# PIC32MZ2048EFM144 device description
Architecture: MIPS; Family: PIC32MZEF; Series: PIC32MZ
Registers are 32-bit, read-write, no defined reset value unless marked. A register's access mark holds for its fields unless they carry their own. Offsets are from the block's base; [hi:lo] are bit positions; {n}, {i} and the like mark numbered series; 'fields as' and 'values as' point back to an identical list; <NAME> marks a mode.

## ADCHS
Instances: ADCHS 0x1f84b000 in periph_pb3_std
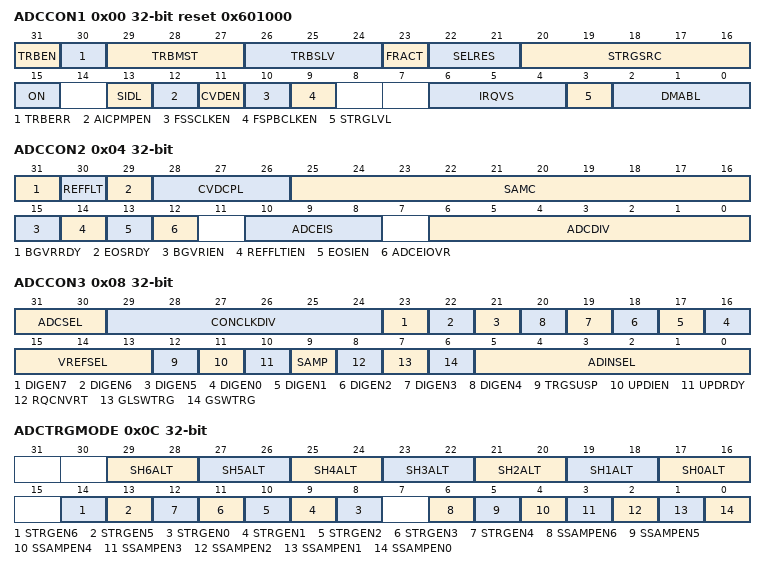
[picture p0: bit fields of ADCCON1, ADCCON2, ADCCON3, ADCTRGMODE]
0x00 ADCCON1 reset 0x601000 — ADC Control Register 1
  [31] TRBEN — Turbo Channel Enable bit
    1=Enable the Turbo channel; 0=Disable the Turbo channel
  [30] TRBERR — Turbo Channel Error Status bit
    1=An error occurred while setting the Turbo channel and Turbo channel function to be disabled regardless of the TRBEN bit being set to 1; 0=Turbo channel error did not occur
  [29:27] TRBMST — Turbo Master ADCx bits
    {v}=ADC{v} is selected as the Turbo Master (v=0..4)
  [26:24] TRBSLV — Turbo Slave ADCx bits
    {v}=ADC{v} is selected as the Turbo Slave (v=0..4)
  [23] FRACT — Fractional Data Output Format bit
    1=Fractional; 0=Integer
  [22:21] SELRES — Shared ADC Resolution bits
    3=12 bits (default); 2=10 bits; 1=8 bits; 0=6 bits
  [20:16] STRGSRC — Scan Trigger Source Select bits
    12=Comparator 2 (COUT); 11=Comparator 1 (COUT); 10=OCMP5; 9=OCMP3; 8=OCMP1; 7=TMR5 match; 6=TMR3 match; 5=TMR1 match; 4=INT0 External interrupt; 2=Global level software trigger (GLSWTRG); 1=Global software edge trigger (GSWTRG); 0=No Trigger
  [15] ON — ADC Module Enable bit
    1=ADC module is enabled; 0=ADC module is disabled
  [13] SIDL — Stop in Idle Mode bit
    1=Discontinue module operation when device enters Idle mode; 0=Continue module operation in Idle mode
  [12] AICPMPEN — Analog Input Charge Pump Enable bit - see datasheet
    1=Analog input charge pump is enabled (default); 0=Analog input charge pump is disabled
  [11] CVDEN — Capacitive Voltage Division Enable bit
    1=CVD operation is enabled; 0=CVD operation is disabled
  [10] FSSCLKEN — Fast Synchronous System Clock to ADC Control Clock bit
    1=Fast synchronous system clock to ADC control clock is enabled; 0=Fast synchronous system clock to ADC control clock is disabled
  [9] FSPBCLKEN — Fast Synchronous Peripheral Clock to ADC Control Clock bit
    1=Fast synchronous peripheral clock to ADC control clock is enabled; 0=Fast synchronous peripheral clock to ADC control clock is disabled
  [6:4] IRQVS — Interrupt Vector Shift bits
    {v}=Shift x left {v} bit position (v=0..7)
  [3] STRGLVL — Scan Trigger High Level/Positive Edge Sensitivity bit
    1=Scan trigger is high level sensitive. Once STRIG mode is selected (TRGSRCx in the ADCTRGx register); 0=Scan trigger is positive edge sensitive. Once STRIG mode is selected (TRGSRCx in the ADCTRGx register)
  [2:0] DMABL
0x04 ADCCON2 — ADC Control Register 2
  [31] BGVRRDY — Band Gap Voltage/ADC Reference Voltage Status bit
    1=Both band gap voltage and ADC reference voltages (Vref) are ready; 0=Either or both band gap voltage and ADC reference voltages (Vref) are not ready
  [30] REFFLT — Band Gap/ Vref / AVdd BOR Fault Status bit
    1=Fault in band gap or the Vref voltage while the ON bit (ADCCON1) was set. Most likely a band gap orVref fault will be caused by a BOR of the analog Vdd supply.; 0=Band gap and Vref voltage are working properly
  [29] EOSRDY — End of Scan Interrupt Status bit
    1=All analog inputs are considered for scanning through the scan trigger (all analog inputs specified in the ADCCSS1 and ADCCSS2 registers) have completed scanning; 0=Scanning has not completed
  [28:26] CVDCPL — Capacitor Voltage Divider Setting bit
    7=7 * 2.5 pF = 17.5 pF; 6=6 * 2.5 pF = 15 pF; 5=5 * 2.5 pF = 12.5 pF; 4=4 * 2.5 pF = 10 pF; 3=3 * 2.5 pF = 7.5 pF; 2=2 * 2.5 pF = 5 pF; 1=1 * 2.5 pF = 2.5 pF; 0=0 * 2.5 pF = 0 pF
  [25:16] SAMC — Sample Time for the Shared ADC bits
    0x3ff=1025 Tad7; 1=3 Tad7; 0=2 Tad7
  [15] BGVRIEN — Band Gap/VREF Voltage Ready Interrupt Enable bit
    1=Interrupt will be generated when the BGVRDDY bit is set; 0=No interrupt is generated when the BGVRRDY bit is set
  [14] REFFLTIEN — Band Gap/VREF Voltage Fault Interrupt Enable bit
    1=Interrupt will be generated when the REFFLT bit is set; 0=No interrupt is generated when the REFFLT bit is set
  [13] EOSIEN — End of Scan Interrupt Enable bit
    1=Interrupt will be generated when EOSRDY bit is set; 0=No interrupt is generated when the EOSRDY bit is set
  [12] ADCEIOVR — Early Interrupt Request Override bit
    1=Early interrupt generation is not overridden and interrupt generation is controlled by the ADCEIEN1 and ADCEIEN2 registers; 0=Early interrupt generation is overridden and interrupt generation is controlled by the ADCGIRQEN1 and ADCGIRQEN2 registers
  [10:8] ADCEIS — Shared ADC Early Interrupt Select bits
    7=The data ready interrupt is generated 8 ADC clocks prior to end of conversion; 6=The data ready interrupt is generated 7 ADC clocks prior to end of conversion; 1=The data ready interrupt is generated 2 ADC module clocks prior to end of conversion; 0=The data ready interrupt is generated 1 ADC module clock prior to end of conversion
  [6:0] ADCDIV — Shared ADC Clock Divider bits
    127=254 * Tq = Tad7; 3=6 * Tq = Tad7; 2=4 * Tq = Tad7; 1=2 * Tq = Tad7
0x08 ADCCON3 — ADC Control Register 3
  [31:30] ADCSEL — Analog-to-Digital Clock Source bits
    3=FRC; 2=REFCLK3; 1=System Clock (Tcy); 0=PBCLK3
  [29:24] CONCLKDIV — Analog-to-Digital Control Clock Divider bits
    63=64 * Tclk = Tq; 3=4 * Tclk = Tq; 2=3 * Tclk = Tq; 1=2 * Tclk = Tq; 0=Tclk = Tq
  [23] DIGEN7 — Shared ADC Digital Enable bit
    1=ADC7 is digital enabled; 0=ADC7 is digital disabled
  [22] DIGEN6
  [21] DIGEN5
  [n+16] DIGEN{n} (n=0..4) — ADC{n} Digital Enable bit
    1=ADC{n} is digital enabled; 0=ADC{n} is digital disabled
  [15:13] VREFSEL — Voltage Reference Input Selection bits
    3=External VREFH and External VREFL; 2=AVDD and External VREFL; 1=External VREFH and AVSS; 0=External AVDD and AVSS
  [12] TRGSUSP — Trigger Suspend bit
    1=Triggers are blocked from starting a new analog-to-digital conversion; 0=Triggers are not blocked
  [11] UPDIEN — Update Ready Interrupt Enable bit
    1=Interrupt will be generated when the UPDRDY bit is set by hardware; 0=No interrupt is generated
  [10] UPDRDY — ADC Update Ready Status bit
    1=ADC SFRs can be updated; 0=ADC SFRs cannot be updated
  [9] SAMP — Class 2 and Class 3 Analog Input Sampling Enable bit
    1=The ADC S&H amplifier is sampling; 0=The ADC S&H amplifier is holding
  [8] RQCNVRT — Individual ADC Input Conversion Request bit
    1=Trigger the conversion of the selected ADC input as specified by the ADINSEL bits; 0=Do not trigger the conversion
  [7] GLSWTRG — Global Level Software Trigger bit
    1=Trigger conversion for ADC inputs that have selected the GLSWTRG bit as the trigger signal; 0=Do not trigger an analog-to-digital conversion
  [6] GSWTRG — Global Software Trigger bit
    1=Trigger conversion for ADC inputs that have selected the GSWTRG bit as the trigger signal; 0=Do not trigger an analog-to-digital conversion
  [5:0] ADINSEL — Analog Input Select bits
    44=MAX_AN_INPUT + 2 = IVTEMP; 43=MAX_AN_INPUT + 1 = IVREF; 42=MAX_AN_INPUT = AN[MAX_AN_INPUT]; 1=AN1; 0=AN0
0x0C ADCTRGMODE — ADC Triggering Mode for Dedicated ADC Register
  [29:28] SH6ALT
  [27:26] SH5ALT
  [2n+17:2n+16] SH{n}ALT (n=0..4) — ADC{n} Analog Input Select bit
    1=AN{n+45}; 0=AN{n}
  [14] STRGEN6
  [13] STRGEN5
  [n+8] STRGEN{n} (n=0..4) — ADC{n} Presynchronized Triggers bit
    1=ADC{n} uses presynchronized triggers; 0=ADC{n} does not use presynchronized triggers
  [6] SSAMPEN6
  [5] SSAMPEN5
  [4] SSAMPEN4 — ADC4 Synchronous Sampling bit
    1=ADC4 uses synchronous sampling for the first sample after being idle or disabled; 0=ADC4 does not use synchronous sampling
  [3] SSAMPEN3 — ADC3 Synchronous Sampling bit
    1=ADC3 uses synchronous sampling for the first sample after being idle or disabled; 0=ADC3 does not use synchronous sampling
  [2] SSAMPEN2 — ADC2Synchronous Sampling bit
    1=ADC2 uses synchronous sampling for the first sample after being idle or disabled; 0=ADC2 does not use synchronous sampling
  [1] SSAMPEN1 — ADC1 Synchronous Sampling bit
    1=ADC1 uses synchronous sampling for the first sample after being idle or disabled; 0=ADC1 does not use synchronous sampling
  [0] SSAMPEN0 — ADC0 Synchronous Sampling bit
    1=ADC0 uses synchronous sampling for the first sample after being idle or disabled; 0=ADC0 does not use synchronous sampling
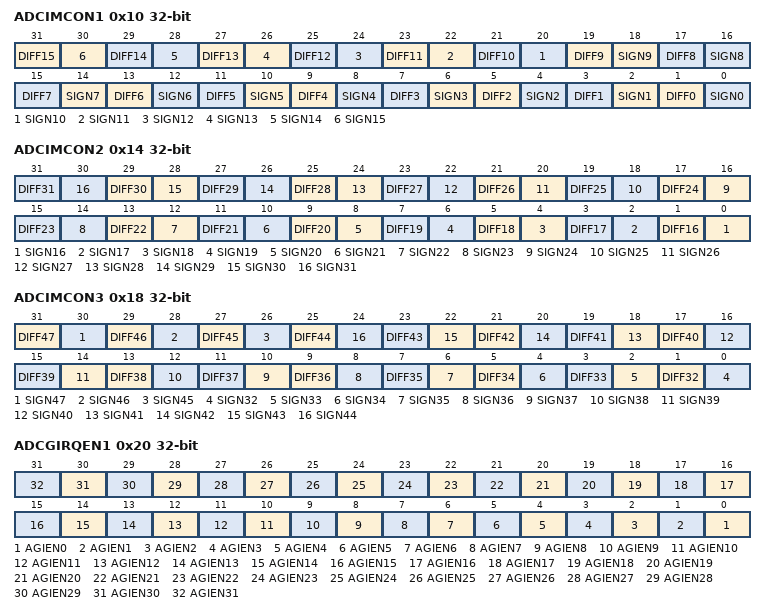
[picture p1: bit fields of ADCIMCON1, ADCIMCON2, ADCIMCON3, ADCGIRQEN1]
0x10 ADCIMCON1 — ADC Input Mode Control Register 1
  [2n+1] DIFF{n} (n=9..15) — AN{n} Mode bit
    1=AN{n} is using Differential mode; 0=AN{n} is using Single-ended mode
  [2n] SIGN{n} (n=0..15) — AN{n} Signed Data Mode bit
    1=AN{n} is using Signed Data mode; 0=AN{n} is using Unsigned Data mode
  [17] DIFF8 — AN 8 Mode bit
    1=AN8 is using Differential mode; 0=AN8 is using Single-ended mode
  [2n+1] DIFF{n} (n=0..7) — AN{n} Mode bit
    values as DIFF9
0x14 ADCIMCON2 — ADC Input Mode Control Register 2
  [2n-31] DIFF{n} (n=16..31) — AN{n} Mode bit
    values as ADCIMCON1.DIFF9
  [2n-32] SIGN{n} (n=16..31) — AN{n} Signed Data Mode bit
    values as ADCIMCON1.SIGN0
0x18 ADCIMCON3 — ADC Input Mode Control Register 3
  [31] DIFF47
  [30] SIGN47
  [29] DIFF46
  [28] SIGN46
  [27] DIFF45
  [26] SIGN45
  [2n-63] DIFF{n} (n=32..44) — AN{n} Mode bit
    values as ADCIMCON1.DIFF9
  [2n-64] SIGN{n} (n=32..44) — AN{n} Signed Data Mode bit
    values as ADCIMCON1.SIGN0
0x20 ADCGIRQEN1 — ADC Global Interrupt Enable Register 1
  [all] fields
    1=Interrupts are enabled for the selected analog input. The interrupt is generated after the converted data is ready (indicated by the ARDYx bit (x = 31-0) of the ADCDSTAT1 register); 0=Interrupts are disabled
  [n] AGIEN{n} (n=0..31) — ADC Global Interrupt Enable bits for analog input {n}
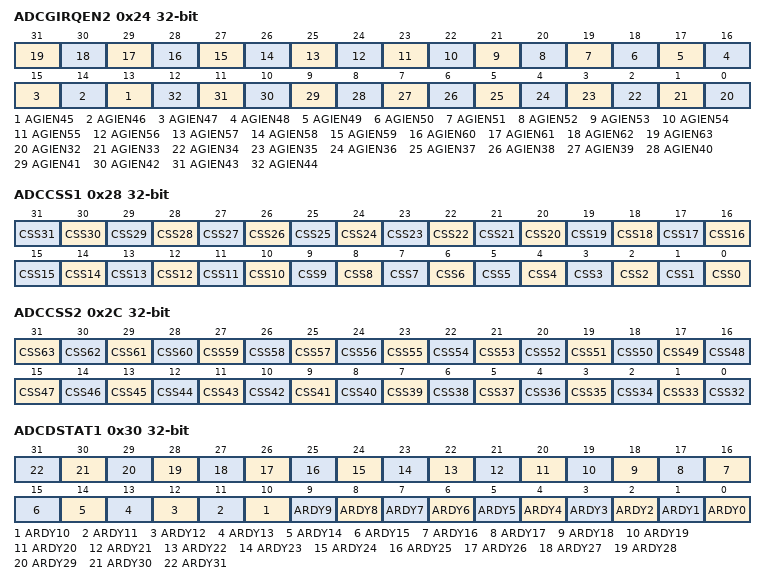
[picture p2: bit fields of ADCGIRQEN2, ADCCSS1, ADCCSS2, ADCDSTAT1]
0x24 ADCGIRQEN2 — ADC Global Interrupt Enable Register 2
  [n-32] AGIEN{n} (n=45..63)
  [n-32] AGIEN{n} (n=32..44) — ADC Global Interrupt Enable bits for analog input {n}
    values as the fields of ADCGIRQEN1
0x28 ADCCSS1 — ADC Common Scan Select Register 1
  [all] fields
    1=Select ANx for input scan; 0=Skip ANx for input scan
  [n] CSS{n} (n=0..31) — Analog Common Scan Select bits {n}
0x2C ADCCSS2 — ADC Common Scan Select Register 2
  [n-32] CSS{n} (n=45..63)
  [12] CSS44 — Analog Common Scan Select bits 44
    1=Select ANx for input scan; 0=Skip ANx for input scan; 1=Select ANx for input scan; 0=Skip ANx for input scan
  [n-32] CSS{n} (n=33..43) — Analog Common Scan Select bits {n}
    1=Select ANx for input scan; 0=Skip ANx for input scan
  [0] CSS32
0x30 ADCDSTAT1 ro — ADC Data Ready Status Register 1
  [all] fields
    1=This bit is set when converted data is ready in the data register; 0=This bit is cleared when the associated data register is read
  [n] ARDY{n} (n=0..31) — Conversion Data Ready for Corresponding Analog Input Ready bit {n}
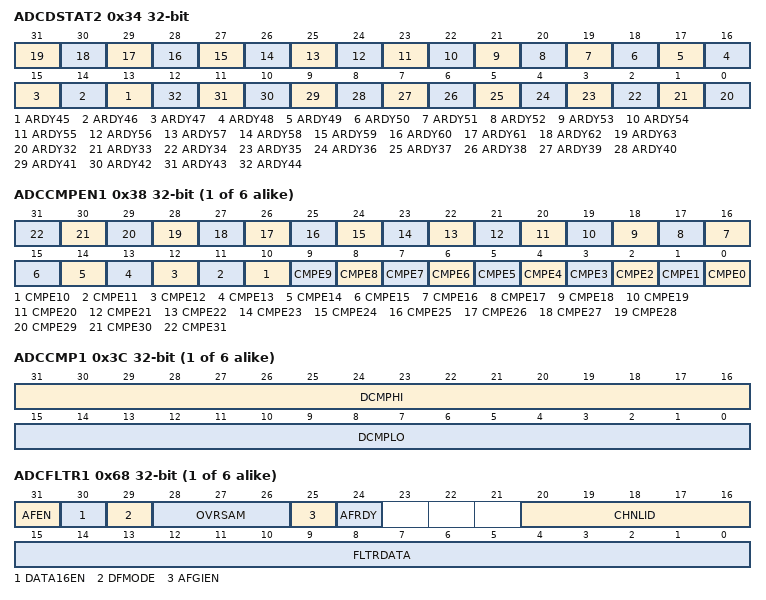
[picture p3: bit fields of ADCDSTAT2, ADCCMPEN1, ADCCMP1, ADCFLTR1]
0x34 ADCDSTAT2 ro — ADC Data Ready Status Register 2
  [n-32] ARDY{n} (n=45..63)
  [n-32] ARDY{n} (n=32..44) — Conversion Data Ready for Corresponding Analog Input Ready bit {n}
    values as the fields of ADCDSTAT1
{0x30+8i} ADCCMPEN{i} (i=1..6) — ADC Digital Comparator x Enable Register (x = 1 through 6)
  [n] CMPE{n} (n=0..31)
{0x34+8i} ADCCMP{i} (i=1..6) — ADC Digital Comparator x Limit Value Register (x = 1 through 6)
  [31:16] DCMPHI, [15:0] DCMPLO
{0x64+4i} ADCFLTR{i} (i=1..6) — ADC Digital Filter x Register (x = 1 through 6)
  [31] AFEN — Digital Filter x Enable bit
    1=Digital filter is enabled; 0=Digital filter is disabled and the AFRDY status bit is cleared
  [30] DATA16EN — Filter Significant Data Length bit
    1=All 16 bits of the filter output data are significant; 0=Only the first 12 bits are significant
  [29] DFMODE — ADC Filter Mode bit
    1=Filter x works in Averaging mode; 0=Filter x works in Oversampling Filter mode (default)
  [28:26] OVRSAM — Oversampling Filter Ratio bits
    7=(If DFMODE is 0) 128 samples (shift sum 3 bits to right; 6=(If DFMODE is 0) 32 samples (shift sum 2 bits to right; 5=(If DFMODE is 0) 8 samples (shift sum 1 bit to right; 4=(If DFMODE is 0) 2 samples (shift sum 0 bits to right; 3=(If DFMODE is 0) 256 samples (shift sum 4 bits to right; 2=(If DFMODE is 0) 64 samples (shift sum 3 bits to right; 1=(If DFMODE is 0) 16 samples (shift sum 2 bits to right; 0=(If DFMODE is 0) 4 samples (shift sum 1 bit to right
  [25] AFGIEN — Digital Filter x Interrupt Enable bit
    1=Digital filter interrupt is enabled and is generated by the AFRDY status bit; 0=Digital filter is disabled
  [24] AFRDY — Digital Filter x Data Ready Status bit
    1=Data is ready in the FLTRDATA bits; 0=Data is not ready
  [20:16] CHNLID — Digital Filter Analog Input Selection bits
    11=AN11; 2=AN2; 1=AN1; 0=AN0
  [15:0] FLTRDATA
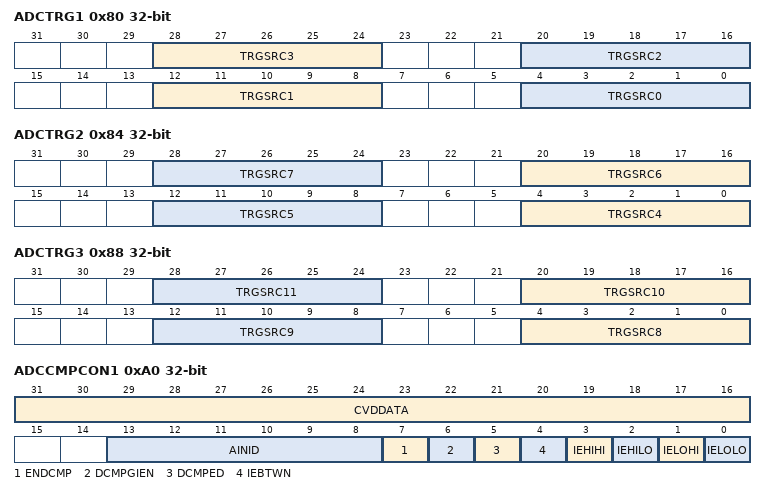
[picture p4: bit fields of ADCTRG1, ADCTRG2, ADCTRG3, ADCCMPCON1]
0x80 ADCTRG1 — ADC Trigger Source 1 Register
  [all] fields
    12=Comparator 2 (COUT); 11=Comparator 1 (COUT); 10=OCMP5; 9=OCMP3; 8=OCMP1; 7=TMR5 match; 6=TMR3 match; 5=TMR1 match; 4=INT0 External interrupt; 3=STRIG; 2=Global level software trigger (GLSWTRG); 1=Global software edge Trigger (GSWTRG); 0=No Trigger
  [28:24] TRGSRC3 — Trigger Source for Conversion of Analog Input AN3 Select bits
  [20:16] TRGSRC2 — Trigger Source for Conversion of Analog Input AN2 Select
  [12:8] TRGSRC1 — Trigger Source for Conversion of Analog Input AN1 Select bits
  [4:0] TRGSRC0 — Trigger Source for Conversion of Analog Input AN0 Select bits
0x84 ADCTRG2 — ADC Trigger Source 2 Register
  [all] fields
    values as the fields of ADCTRG1
  [8n-28:8n-32] TRGSRC{n} (n=4..7) — Trigger Source for Conversion of Analog Input AN{n} Select bits
0x88 ADCTRG3 — ADC Trigger Source 3 Register
  [all] fields
    values as the fields of ADCTRG1
  [8n-60:8n-64] TRGSRC{n} (n=8..11) — Trigger Source for Conversion of Analog Input AN{n} Select bits
0xA0 ADCCMPCON1 — ADC Digital Comparator 1 Control Register
  [31:16] CVDDATA
  [13:8] AINID — Digital Comparator 0 Analog Input Identification bits
    44=AN44 is being monitored; 43=AN43 is being monitored; 1=AN1 is being monitored; 0=AN0 is being monitored
  [7] ENDCMP — Digital Comparator 0 Enable bit
    1=Digital Comparator 0 is enabled; 0=Digital Comparator 0 is not enabled
  [6] DCMPGIEN — Digital Comparator 0 Global Interrupt Enable bit
    1=A Digital Comparator 0 interrupt is generated when the DCMPED status bit (ADCCMP0CON) is set; 0=A Digital Comparator 0 interrupt is disabled
  [5] DCMPED — Digital Comparator 0 Output True Event Status bit
    1=Digital Comparator 0 output true event has occurred (output of Comparator is 1); 0=Digital Comparator 0 output is false (output of comparator is 0)
  [4] IEBTWN — Between Low/High Digital Comparator 0 Event bit
    1=Generate a digital comparator event when DCMPLO < DATA<31:0> < DCMPHI<15:0>; 0=Do not generate a digital comparator event
  [3] IEHIHI — High/High Digital Comparator 0 Event bit
    1=Generate a Digital Comparator 0 Event when DCMPHI < DATA<31:0>; 0=Do not generate an event
  [2] IEHILO — High/Low Digital Comparator 0 Event bit
    1=Generate a Digital Comparator 0 Event when DATA < DCMPHI<15:0>; 0=Do not generate an event
  [1] IELOHI — Low/High Digital Comparator 0 Event bit
    1=Generate a Digital Comparator 0 Event when DCMPLO < DATA<31:0>; 0=Do not generate an event
  [0] IELOLO — Low/Low Digital Comparator 0 Event bit
    1=Generate a Digital Comparator 0 Event when DATA < DCMPLO<15:0>; 0=Do not generate an event
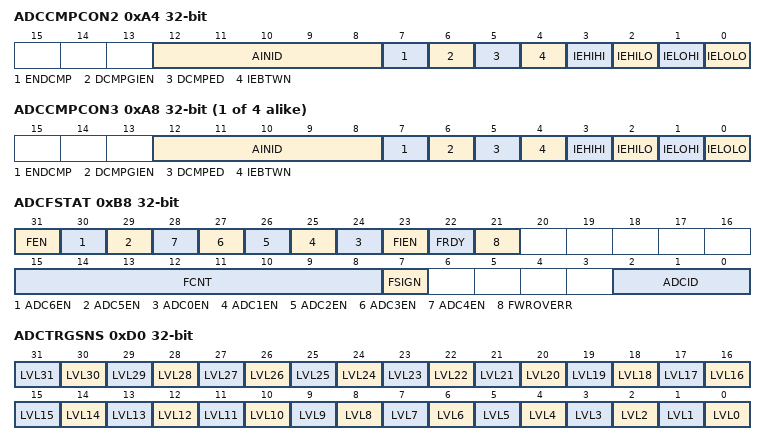
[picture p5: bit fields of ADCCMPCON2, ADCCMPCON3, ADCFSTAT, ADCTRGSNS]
0xA4 ADCCMPCON2 — ADC Digital Comparator 2 Control Register
  [12:8] AINID — Digital Comparator 1 Analog Input Identification bits
    31=AN31 is being monitored; 30=AN30 is being monitored; 1=AN1 is being monitored; 0=AN0 is being monitored
  [7] ENDCMP — Digital Comparator 1 Enable bit
    1=Digital Comparator x is enabled; 0=Digital Comparator x is not enabled
  [6] DCMPGIEN — Digital Comparator 1 Global Interrupt Enable bit
    1=A Digital Comparator x interrupt is generated when the DCMPED status bit (ADCCMPxCON) is set; 0=A Digital Comparator x interrupt is disabled
  [5] DCMPED — Digital Comparator 1 Output True Event Status bit
    1=Digital Comparator x output true event has occurred (output of Comparator is 1); 0=Digital Comparator x output is false (output of Comparator is 0)
  [4] IEBTWN — Between Low/High Digital Comparator 1 Event bit
    1=Generate a digital comparator event when the DCMPLO < DATA<31:0> bits< DCMPHI<15:0> bits; 0=Do not generate a digital comparator event
  [3] IEHIHI — High/High Digital Comparator 1 Event bit
    1=Generate a Digital Comparator x Event when the DCMPHI bits < DATA<31:0> bits; 0=Do not generate an event
  [2] IEHILO — High/Low Digital Comparator 1 Event bit
    1=Generate a Digital Comparator x Event when the DATA bits < DCMPHI<15:0> bits; 0=Do not generate an event
  [1] IELOHI — Low/High Digital Comparator 1 Event bit
    1=Generate a Digital Comparator x Event when the DCMPLO < DATA<31:0> bits; 0=Do not generate an event
  [0] IELOLO — Low/Low Digital Comparator 1 Event bit
    1=Generate a Digital Comparator x Event when the DATA bits < DCMPLO<15:0> bits; 0=Do not generate an event
{0x9C+4i} ADCCMPCON{i} (i=3..6) — ADC Digital Comparator {i} Control Register
  [12:8] AINID — Digital Comparator x Analog Input Identification bits
    values as ADCCMPCON2.AINID
  [7] ENDCMP — Digital Comparator x Enable bit
    values as ADCCMPCON2.ENDCMP
  [6] DCMPGIEN — Digital Comparator x Global Interrupt Enable bit
    values as ADCCMPCON2.DCMPGIEN
  [5] DCMPED — Digital Comparator x Output True Event Status bit
    values as ADCCMPCON2.DCMPED
  [4] IEBTWN — Between Low/High Digital Comparator x Event bit
    values as ADCCMPCON2.IEBTWN
  [3] IEHIHI — High/High Digital Comparator x Event bit
    values as ADCCMPCON2.IEHIHI
  [2] IEHILO — High/Low Digital Comparator x Event bit
    values as ADCCMPCON2.IEHILO
  [1] IELOHI — Low/High Digital Comparator x Event bit
    values as ADCCMPCON2.IELOHI
  [0] IELOLO — Low/Low Digital Comparator x Event bit
    values as ADCCMPCON2.IELOLO
0xB8 ADCFSTAT — ADC FIFO Status Register
  [31] FEN — FIFO Enable bit
    1=FIFO is enabled; 0=FIFO is disabled; no data is being saved into the FIFO
  [30] ADC6EN
  [29] ADC5EN
  [n+24] ADC{n}EN (n=0..4) — ADC{n} Enable bit
    1=Converted output data of ADC is stored in the FIFO; 0=Converted output data of ADC is not stored in the FIFO
  [23] FIEN — FIFO Interrupt Enable bit
    1=FIFO interrupts are enabled; an interrupt is generated once the FRDY bit is set; 0=FIFO interrupts are disabled
  [22] FRDY — FIFO Data Ready Interrupt Status bit
    1=FIFO has data to be read; 0=No data is available in the FIFO
  [21] FWROVERR — FIFO Write Overflow Error Status bit
    1=A write overflow error in the FIFO has occurred (circular FIFO); 0=A write overflow error in the FIFO has not occurred
  [15:8] FCNT
  [7] FSIGN
  [2:0] ADCID — ADCx Identifier bits
    4=Converted data of ADC4 is stored in FIFO; 0=Converted data of ADC0 is stored in FIFO
0xBC ADCFIFO ro — ADC FIFO Data Register
  [31:0] DATA
0xC0 ADCBASE
  [15:0] ADCBASE
0xD0 ADCTRGSNS — ADC Trigger Level/Edge Sensitivity Register
  [n] LVL{n} (n=12..31)
  [n] LVL{n} (n=0..11) — Trigger Level and Edge Sensitivity bit {n}
    1=Analog input is sensitive to the high level of its trigger (level sensitivity implies retriggering as long as the trigger signal remains high); 0=Analog input is sensitive to the positive edge of its trigger (this is the value after a reset)
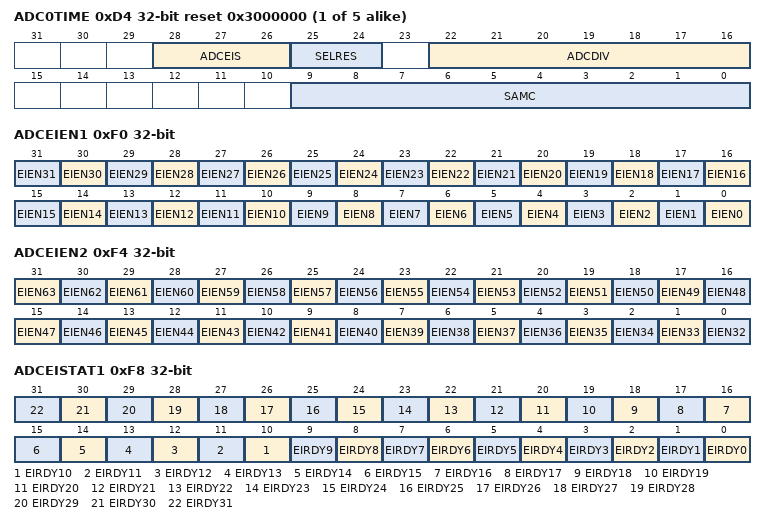
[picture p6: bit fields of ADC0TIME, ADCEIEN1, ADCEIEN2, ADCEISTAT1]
{0xD4+4i} ADC{i}TIME reset 0x3000000 (i=0..4) — Dedicated ADC{i} Timing Register x (x = 0 through 4)
  [28:26] ADCEIS — ADC{i} Early Interrupt Select bits
    {v}=The data ready interrupt is generated {v+1} ADC clocks prior to the end of conversion (v=1..7); 0=The data ready interrupt is generated 1 ADC clock prior to the end of conversion
  [25:24] SELRES — ADC{i} Resolution Select bits
    3=12 bits; 2=10 bits; 1=8 bits; 0=6 bits
  [22:16] ADCDIV — ADC{i} Clock 2x Divisor bits
    127=254 * Tq = Tadx; 3=6 * Tq = Tadx; 2=4 * Tq = Tadx; 1=2 * Tq = Tadx
  [9:0] SAMC — ADC{i} Sample Time bits
    0x3ff=1025 Tadx; 1=3 Tadx; 0=2 Tadx
0xF0 ADCEIEN1 — ADC Early Interrupt Enable Register 1
  [all] fields
    1=Early Interrupts are enabled for the selected analog input. The interrupt is generated after the early interrupt event occurs; 0=Interrupts are disabled
  [n] EIEN{n} (n=0..31) — Early Interrupt Enable for Analog Input bit {n}
0xF4 ADCEIEN2 — ADC Early Interrupt Enable Register 2
  [n-32] EIEN{n} (n=45..63)
  [n-32] EIEN{n} (n=32..44) — Early Interrupt Enable for Analog Input bit {n}
    values as the fields of ADCEIEN1
0xF8 ADCEISTAT1 ro — ADC Early Interrupt Status Register 1
  [all] fields
    1=This bit is set when the early interrupt event occurs for the specified analog input. An interrupt will be generated if early interrupts are enabled in the ADCEIEN1 register. For the Class 1 analog inputs; 0=Interrupts are disabled
  [n] EIRDY{n} (n=0..31) — Early Interrupt for Corresponding Analog Input Ready bit {n}
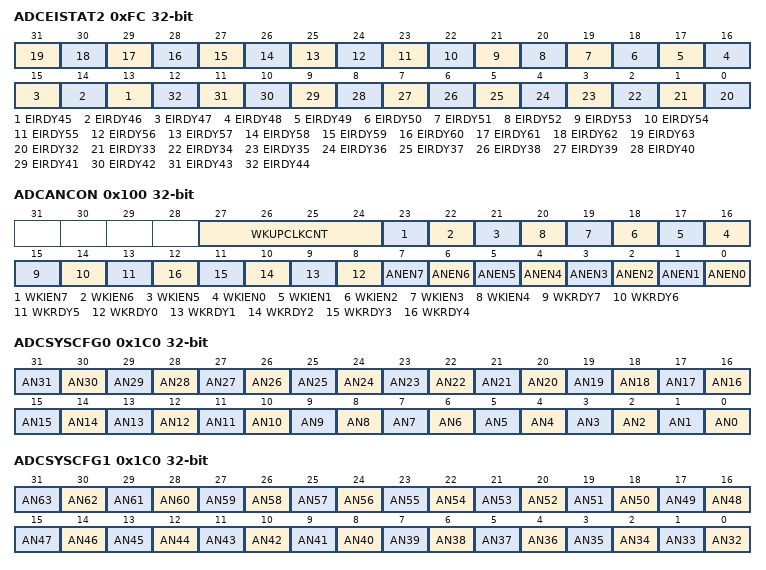
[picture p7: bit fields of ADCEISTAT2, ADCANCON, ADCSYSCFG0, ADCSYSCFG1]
0xFC ADCEISTAT2 ro — ADC Early Interrupt Status Register 2
  [n-32] EIRDY{n} (n=45..63)
  [n-32] EIRDY{n} (n=32..44) — Early Interrupt for Corresponding Analog Input Ready bit {n}
    1=This bit is set when the early interrupt event occurs for the specified analog input. An interrupt will be generated if early interrupts are enabled in the ADCEIEN2 register. For the Class 1 analog inputs; 0=Interrupts are disabled
0x100 ADCANCON — ADC Analog Warm-up Control Register
  [27:24] WKUPCLKCNT — Wake-up Clock Count bits
    15=32; 6=64 clocks; 5=32 clocks; {v}=16 clocks (v=0..4)
  [23] WKIEN7 — Shared ADC Wake-up Interrupt Enable bit
    1=Enable interrupt and generate interrupt when the WKRDY7 status bit is set; 0=Disable interrupt
  [22] WKIEN6
  [21] WKIEN5
  [n+16] WKIEN{n} (n=0..4) — ADC {n} Wake-up Interrupt Enable bit
    1=Enable interrupt and generate interrupt when the WKRDYx status bit is set; 0=Disable interrupt
  [15] WKRDY7 — Shared ADC Wake-up Status bit
    1=ADC7 Analog and Bias circuitry ready after the wake-up count number 2WKUPEXP clocks after setting ANEN7 to 1; 0=ADC7 Analog and Bias circuitry is not ready
  [14] WKRDY6
  [13] WKRDY5
  [n+8] WKRDY{n} (n=0..4) — ADC {n} Wake-up Status bit
    1=ADCx Analog and Bias circuitry ready after the wake-up count number 2WKUPEXP clocks after setting ANENx to 1; 0=ADCx Analog and Bias circuitry is not ready
  [7] ANEN7 — Shared ADC Analog and Bias Circuitry Enable bit
    1=Analog and bias circuitry enabled. Once the analog and bias circuit is enabled; 0=Analog and bias circuitry disabled
  [6] ANEN6
  [5] ANEN5
  [n] ANEN{n} (n=0..4) — ADC{n} Analog and Bias Circuitry Enable bit
    values as ANEN7
{0x180+4i} ADC{i}CFG (i=0..4) — ADC{i} Configuration Register
  [31:0] ADCCFG
0x19C ADC7CFG — ADC7 Configuration Register
  [31:0] ADCCFG
0x1C0 ADCSYSCFG0 ro
  [n] AN{n} (n=0..31)
0x1C0 ADCSYSCFG1 ro — ADC System Configuration Register 1
  [n-32] AN{n} (n=32..63)
{0x200+4i} ADCDATA{i} (i=0..44) — ADC{i} Output Data Register
  [31:0] DATA

## Notices in the file
Copyright (c) 2017 Microchip Technology Inc.
SPDX-License-Identifier: Apache-2.0
Licensed under the Apache License, Version 2.0 (the "License");
you may not use this file except in compliance with the License.
You may obtain a copy of the License at
http://www.apache.org/licenses/LICENSE-2.0
Unless required by applicable law or agreed to in writing, software
distributed under the License is distributed on an "AS IS" BASIS,
WITHOUT WARRANTIES OR CONDITIONS OF ANY KIND, either express or implied.
See the License for the specific language governing permissions and
limitations under the License.
